AUTOSAR XML (schema 00044)
package /ComponentTypes
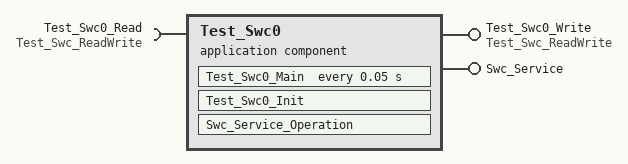
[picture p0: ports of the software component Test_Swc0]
  application sw component type Test_Swc0
    provide port Test_Swc0_Write: nonqueued-sender-com-spec{data-element=u8_Signal, init-value=0}, provided-interface=Test_Swc_ReadWrite
    require port Test_Swc0_Read: nonqueued-receiver-com-spec{data-element=u8_Signal, init-value=0}, required-interface=Test_Swc_ReadWrite
    provide port Swc_Service: server-com-spec{operation=Operation, queue-length=1}, provided-interface=Swc_Service
    behavior Test_Swc0_InternalBehavior
      init event Test_Swc0_InitEvent: start-on-event=Test_Swc0_Init
      timing event TMT_Test_Swc0_Main: start-on-event=Test_Swc0_Main, period=0.05
      operation invoked event OIT_Swc_Service_Operation_Swc_Service_Operation: start-on-event=Swc_Service_Operation, operation=Swc_Service.Operation
      runnable Test_Swc0_Init
      runnable Test_Swc0_Main: minimum-start-interval=0.05
        data-receive-point-by-arguments:
          access REC_Test_Swc0_Read_u8_Signal: accessed-variable=Test_Swc0_Read.u8_Signal
        data-send-points:
          access SEND_Test_Swc0_Write_u8_Signal: accessed-variable=Test_Swc0_Write.u8_Signal
      runnable Swc_Service_Operation
  swc implementation Test_Swc0_Implementation: behavior=Test_Swc0_InternalBehavior
